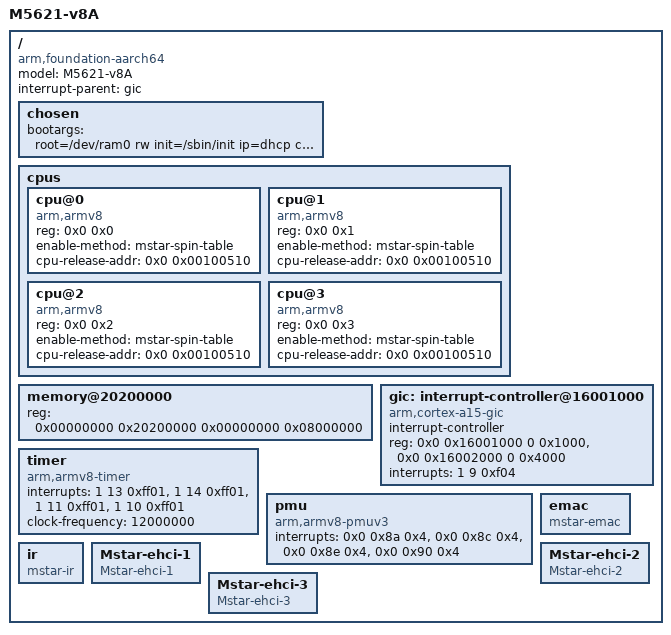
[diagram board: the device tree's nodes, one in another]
/*
 * ARM Ltd.
 *
 * ARMv8 Foundation model DTS
 */

/dts-v1/;
/ {
	model = "M5621-v8A";
	compatible = "arm,foundation-aarch64", "arm,m5621";
	interrupt-parent = <&gic>;
	#address-cells = <2>;
	#size-cells = <2>;

    /* rdinit=/sbin/init */
	chosen {
         bootargs = "root=/dev/ram0 rw init=/sbin/init ip=dhcp console=ttyS0,38400,LX_MEM=0x03000000";
        };

	cpus {
		#address-cells = <2>;
		#size-cells = <0>;

		cpu@0 {
			device_type = "cpu";
			compatible = "arm,armv8";
			reg = <0x0 0x0>;
			enable-method = "mstar-spin-table";
			cpu-release-addr = <0x0 0x00100510>;
		};
		cpu@1 {
			device_type = "cpu";
			compatible = "arm,armv8";
			/* reg = <0x0 0x1>; */
			/* 0x0 is high 32bit, 0x100 is low 32bit ==> this means this cpu's CPUID (MPIDR_EL1)*/
			reg = <0x0 0x1>;
			enable-method = "mstar-spin-table";
			cpu-release-addr = <0x0 0x00100510>;
		};
		cpu@2 {
                        device_type = "cpu";
                        compatible = "arm,armv8";
                        /* reg = <0x0 0x1>; */
                        /* 0x0 is high 32bit, 0x100 is low 32bit ==> this means this cpu's CPUID (MPIDR_EL1)*/
                        reg = <0x0 0x2>;
                        enable-method = "mstar-spin-table";
                        cpu-release-addr = <0x0 0x00100510>;
                };
		cpu@3 {
                        device_type = "cpu";
                        compatible = "arm,armv8";
                        /* reg = <0x0 0x1>; */
                        /* 0x0 is high 32bit, 0x100 is low 32bit ==> this means this cpu's CPUID (MPIDR_EL1)*/
                        reg = <0x0 0x3>;
                        enable-method = "mstar-spin-table";
                        cpu-release-addr = <0x0 0x00100510>;
                };
	};

	memory@20200000 {
		device_type = "memory";
		reg = <0x00000000 0x20200000 0x00000000 0x08000000>;
	};

	gic: interrupt-controller@16001000 {
		compatible = "arm,cortex-a15-gic", "arm,cortex-a9-gic";
		#interrupt-cells = <3>;
		#address-cells = <0>;
		interrupt-controller;
		reg = <0x0 0x16001000 0 0x1000>,
		      <0x0 0x16002000 0 0x4000>;
		interrupts = <1 9 0xf04>;
	};

	timer {
		compatible = "arm,armv8-timer";
		interrupts = <1 13 0xff01>,
			     <1 14 0xff01>,
			     <1 11 0xff01>,
			     <1 10 0xff01>;
		clock-frequency = <12000000>;
	};

	pmu {
		compatible = "arm,armv8-pmuv3";
		interrupts = <0x0 0x8a 0x4>,
			<0x0 0x8c 0x4>,
			<0x0 0x8e 0x4>,
			<0x0 0x90 0x4>;
	};

	emac {
	        compatible = "mstar-emac";
	};

	ir {
	        compatible = "mstar-ir";
	};

	Mstar-ehci-1 {
		compatible = "Mstar-ehci-1";
	};

	Mstar-ehci-2 {
		compatible = "Mstar-ehci-2";
	};

	Mstar-ehci-3 {
		compatible = "Mstar-ehci-3";
	};
};
